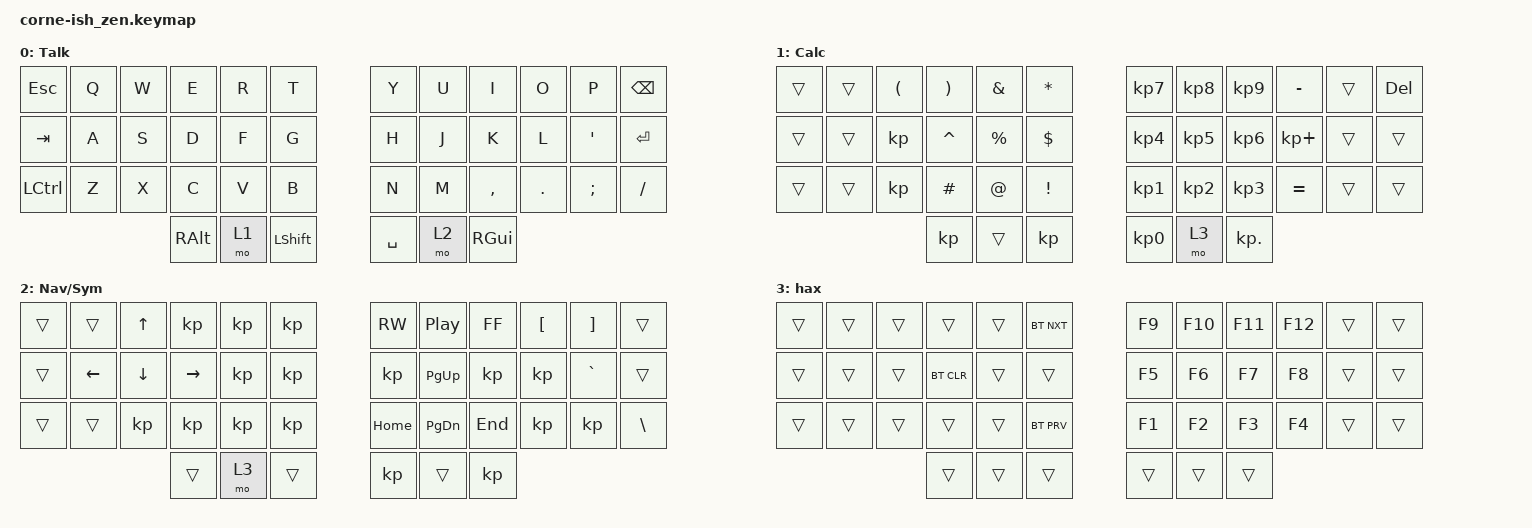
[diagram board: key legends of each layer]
/*
*
* Copyright (c) 2021 Darryl deHaan
* SPDX-License-Identifier: MIT
*
*/

#include <behaviors.dtsi>
#include <dt-bindings/zmk/keys.h>
#include <dt-bindings/zmk/bt.h>

/ {
        keymap {
                compatible = "zmk,keymap";

                default_layer {
                        label = "Talk";
// -----------------------------------------------------------------------------------------
// | ESC |  Q  |  W  |  E  |  R  |  T  |   |  Y  |  U  |  I  |  O  |  P  | BKSP |
// | TAB |  A  |  S  |  D  |  F  |  G  |   |  H  |  J  |  K  |  L  |  ;  |  '   |
// | CTR |  Z  |  X  |  C  |  V  |  B  |   |  N  |  M  |  ,  |  .  |  /  | ESC  |
//                   | ALT | LWR | SHF |   | SPC | RSE | GUI |
                        bindings = <
   &kp ESC   &kp Q &kp W &kp E &kp R &kp T       &kp Y &kp U  &kp I     &kp O   &kp P    &kp BSPC
   &kp TAB   &kp A &kp S &kp D &kp F &kp G       &kp H &kp J  &kp K     &kp L   &kp SQT  &kp RET
   &kp LCTRL &kp Z &kp X &kp C &kp V &kp B       &kp N &kp M  &kp COMMA &kp DOT &kp SEMI &kp FSLH
                      &kp RALT &mo 1 &kp LSHFT   &kp SPACE &mo 2 &kp RGUI
                        >;
                };
                number_layer {
                        label = "Calc";
                        bindings = <
   &trans &trans &kp LPAR &kp RPAR   &kp AMPS  &kp STAR     &kp KP_N7 &kp KP_N8 &kp KP_N9 &kp MINUS   &trans &kp DEL
   &trans &trans &kp      &kp CARET  &kp PRCNT &kp DLLR     &kp KP_N4 &kp KP_N5 &kp KP_N6 &kp KP_PLUS &trans &trans
   &trans &trans &kp      &kp HASH   &kp AT    &kp EXCL     &kp KP_N1 &kp KP_N2 &kp KP_N3 &kp EQUAL   &trans &trans
                    &kp        &trans    &kp                &kp KP_N0 &mo 3     &kp KP_DOT
                        >;
                };
                nav_layer {
                        label = "Nav/Sym";
                        bindings = <
   &trans &trans   &kp UP   &kp       &kp   &kp       &kp C_RW &kp C_PP  &kp C_FF &kp LBKT &kp RBKT  &trans
   &trans &kp LEFT &kp DOWN &kp RIGHT &kp   &kp       &kp      &kp PG_UP &kp      &kp      &kp GRAVE &trans
   &trans &trans   &kp      &kp       &kp   &kp       &kp HOME &kp PG_DN &kp END  &kp      &kp       &kp BSLH
                            &trans    &mo 3 &trans    &kp      &trans    &kp
                        >;
                };
                power_layer {
                        label = "hax";

                        bindings = <
   &trans &trans &trans &trans &trans &bt BT_NXT   &kp F9 &kp F10 &kp F11 &kp F12 &trans &trans
   &trans &trans &trans &bt BT_CLR &trans &trans   &kp F5 &kp F6  &kp F7  &kp F8  &trans &trans
   &trans &trans &trans &trans &trans &bt BT_PRV   &kp F1 &kp F2  &kp F3  &kp F4  &trans &trans 
                        &trans &trans &trans   &trans &trans &trans 
                        >;
                };

        };
};
